VERSION ""

NS_ :

BS_:

BU_: Body_Control Door_Module Light_Module Chassis_ECU

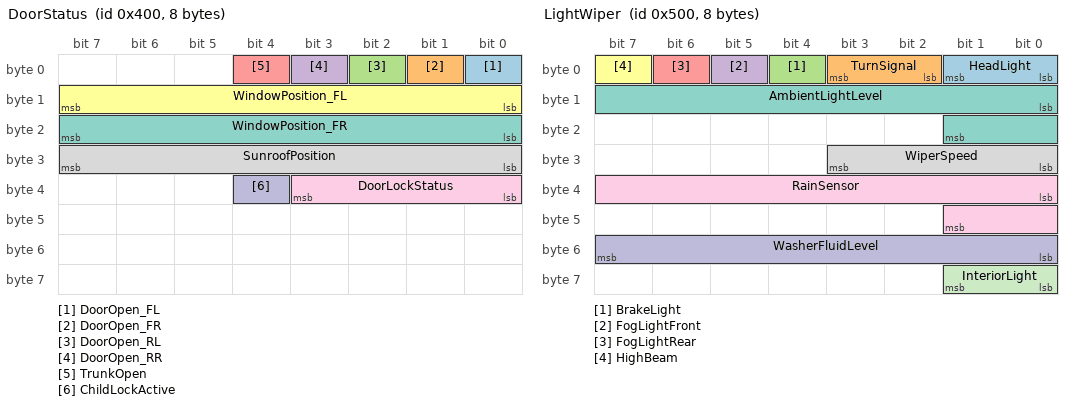
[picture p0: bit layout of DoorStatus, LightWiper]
BO_ 1024 DoorStatus: 8 Door_Module
 SG_ DoorOpen_FL : 0|1@1+ (1,0) [0|1] "" Body_Control
 SG_ DoorOpen_FR : 1|1@1+ (1,0) [0|1] "" Body_Control
 SG_ DoorOpen_RL : 2|1@1+ (1,0) [0|1] "" Body_Control
 SG_ DoorOpen_RR : 3|1@1+ (1,0) [0|1] "" Body_Control
 SG_ TrunkOpen : 4|1@1+ (1,0) [0|1] "" Body_Control
 SG_ WindowPosition_FL : 8|8@1+ (0.4,0) [0|100] "%" Body_Control
 SG_ WindowPosition_FR : 16|8@1+ (0.4,0) [0|100] "%" Body_Control
 SG_ SunroofPosition : 24|8@1+ (0.4,0) [0|100] "%" Body_Control
 SG_ DoorLockStatus : 32|4@1+ (1,0) [0|15] "" Body_Control
 SG_ ChildLockActive : 36|1@1+ (1,0) [0|1] "" Body_Control

BO_ 1280 LightWiper: 8 Light_Module
 SG_ HeadLight : 0|2@1+ (1,0) [0|3] "" Body_Control
 SG_ TurnSignal : 2|2@1+ (1,0) [0|3] "" Body_Control
 SG_ BrakeLight : 4|1@1+ (1,0) [0|1] "" Body_Control
 SG_ FogLightFront : 5|1@1+ (1,0) [0|1] "" Body_Control
 SG_ FogLightRear : 6|1@1+ (1,0) [0|1] "" Body_Control
 SG_ HighBeam : 7|1@1+ (1,0) [0|1] "" Body_Control
 SG_ AmbientLightLevel : 8|10@1+ (0.1,0) [0|100] "lux" Body_Control
 SG_ WiperSpeed : 24|4@1+ (1,0) [0|15] "" Body_Control
 SG_ RainSensor : 32|10@1+ (0.1,0) [0|100] "" Body_Control
 SG_ WasherFluidLevel : 48|8@1+ (0.4,0) [0|100] "%" Body_Control
 SG_ InteriorLight : 56|2@1+ (1,0) [0|3] "" Body_Control

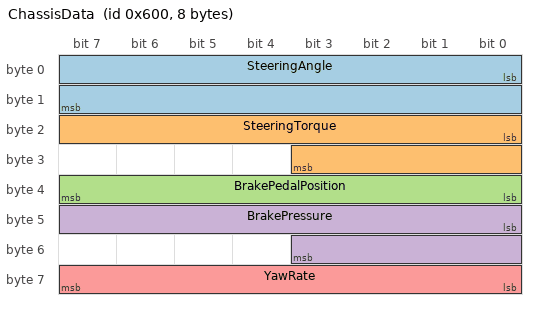
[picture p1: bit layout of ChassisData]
BO_ 1536 ChassisData: 8 Chassis_ECU
 SG_ SteeringAngle : 0|16@1- (0.1,0) [-3276.8|3276.7] "deg" Body_Control
 SG_ SteeringTorque : 16|12@1+ (0.01,0) [0|40.95] "Nm" Body_Control
 SG_ BrakePedalPosition : 32|8@1+ (0.4,0) [0|100] "%" Body_Control
 SG_ BrakePressure : 40|12@1+ (1,0) [0|4095] "kPa" Body_Control
 SG_ YawRate : 56|8@1- (0.5,0) [-64|63.5] "deg/s" Body_Control

CM_ BO_ 1024 "Door and window status - 200ms cycle";
CM_ SG_ 1024 DoorOpen_FL "Front left door open status - 0:Closed, 1:Open";
CM_ SG_ 1024 DoorLockStatus "Door lock status: 0:Unlocked, 1:Locked, 2:Superlocked";
CM_ SG_ 1024 ChildLockActive "Child lock active status";

CM_ BO_ 1280 "External lighting and wiper status - 100ms cycle";
CM_ SG_ 1280 HeadLight "Headlight: 0:Off, 1:Position, 2:LowBeam, 3:Auto";
CM_ SG_ 1280 TurnSignal "Turn signal: 0:Off, 1:Left, 2:Right, 3:Hazard";
CM_ SG_ 1280 WiperSpeed "Wiper: 0:Off, 1:Intermittent, 2:Low, 3:High";

CM_ BO_ 1536 "Chassis dynamics data - 10ms cycle";
CM_ SG_ 1536 SteeringAngle "Steering wheel angle, positive = left turn";
CM_ SG_ 1536 YawRate "Vehicle yaw rate";

BA_DEF_ "BusType" STRING ;
BA_DEF_ BO_ "GenMsgCycleTime" INT 0 65535;

BA_ "BusType" "CAN";
BA_ "GenMsgCycleTime" BO_ 1024 200;
BA_ "GenMsgCycleTime" BO_ 1280 100;
BA_ "GenMsgCycleTime" BO_ 1536 10;
